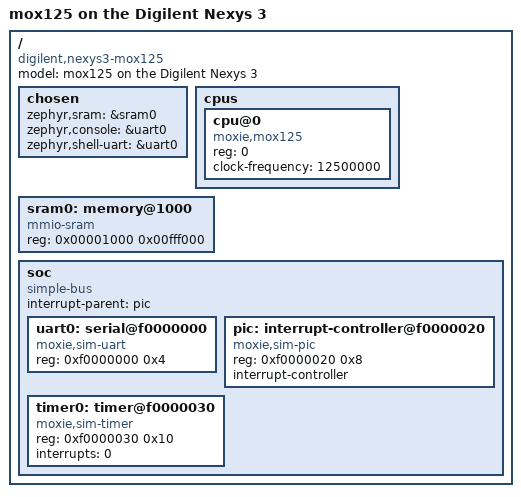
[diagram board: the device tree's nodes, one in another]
/*
 * Copyright (c) 2026 Anthony Green
 *
 * SPDX-License-Identifier: Apache-2.0
 */

/dts-v1/;

/ {
	#address-cells = <1>;
	#size-cells = <1>;
	model = "mox125 on the Digilent Nexys 3";
	compatible = "digilent,nexys3-mox125", "moxie,mox125-sim";

	chosen {
		zephyr,sram = &sram0;
		zephyr,console = &uart0;
		zephyr,shell-uart = &uart0;
	};

	cpus {
		#address-cells = <1>;
		#size-cells = <0>;

		cpu@0 {
			device_type = "cpu";
			compatible = "moxie,mox125";
			reg = <0>;
			/*
			 * What the Muskoka SoC in moxie-cores gives the
			 * core on this board.  Change both together.
			 */
			clock-frequency = <12500000>;
		};
	};

	/*
	 * The board's 16 MB of cellular RAM, less the first page.  The
	 * boot loader in the FPGA loads an image here from the serial
	 * port and starts it at 0x1000.
	 */
	sram0: memory@1000 {
		device_type = "memory";
		compatible = "mmio-sram";
		reg = <0x00001000 0x00fff000>;
	};

	soc {
		#address-cells = <1>;
		#size-cells = <1>;
		compatible = "simple-bus";
		interrupt-parent = <&pic>;
		ranges;

		uart0: serial@f0000000 {
			compatible = "moxie,sim-uart";
			reg = <0xf0000000 0x4>;
			status = "okay";
		};

		pic: interrupt-controller@f0000020 {
			compatible = "moxie,sim-pic";
			reg = <0xf0000020 0x8>;
			interrupt-controller;
			#interrupt-cells = <1>;
		};

		timer0: timer@f0000030 {
			compatible = "moxie,sim-timer";
			reg = <0xf0000030 0x10>;
			interrupts = <0>;
		};
	};
};
